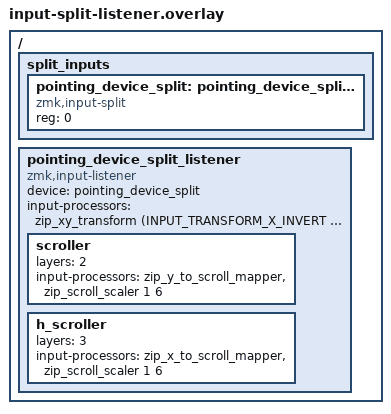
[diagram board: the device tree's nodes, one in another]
/{
    split_inputs {
        #address-cells = <1>;
        #size-cells = <0>;

        pointing_device_split: pointing_device_split@0 {
            compatible = "zmk,input-split";
            reg = <0>;
        };
    };

    pointing_device_split_listener: pointing_device_split_listener {
        compatible = "zmk,input-listener";
        device = <&pointing_device_split>;
        status = "okay";
        input-processors = <&zip_xy_transform (INPUT_TRANSFORM_X_INVERT | INPUT_TRANSFORM_Y_INVERT)>;

        scroller {
            layers = <2>;
            input-processors = <&zip_y_to_scroll_mapper>, <&zip_scroll_scaler 1 6>;
        };

        h_scroller {
            layers = <3>;
            input-processors = <&zip_x_to_scroll_mapper>, <&zip_scroll_scaler 1 6>;
        };
     };
};
